# GD32A72_A74x register map
File version: 1.0
CPU: CM7 r2p1, little endian, MPU, FPU, DSP, 4 interrupt priority bits
Registers are 32-bit, read-write, reset 0x0 unless marked. A register's access mark holds for its fields unless they carry their own. Offsets are from the block's base; [hi:lo] are bit positions.

## RTC — Real-time clock
Base 0x40002800
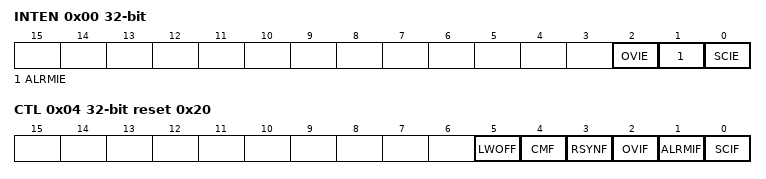
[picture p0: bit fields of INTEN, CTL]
0x00 INTEN — RTC interrupt enable register
  [2] OVIE — Overflow interrupt enable
  [1] ALRMIE — Alarm interrupt enable
  [0] SCIE — Second interrupt enable
0x04 CTL access per field reset 0x20 — RTC control register
  [5] LWOFF ro — Last write operation finished flag
  [4] CMF rw — Configuration mode flag
  [3] RSYNF rw — Registers synchronized flag
  [2] OVIF rw — Overflow interrupt flag
  [1] ALRMIF rw — Alarm interrupt flag
  [0] SCIF rw — Second interrupt flag
0x08 PSCH wo — RTC prescaler high register
  [3:0] PSC — RTC prescaler value high
0x0C PSCL wo reset 0x8000 — RTC prescaler low register
  [15:0] PSC — RTC prescaler value low
0x10 DIVH ro — RTC divider high register
  [3:0] DIV — RTC divider value high
0x14 DIVL ro reset 0x8000 — RTC divider low register
  [15:0] DIV — RTC divider value low
0x18 CNTH — RTC counter high register
  [15:0] CNT — RTC counter value high
0x1C CNTL — RTC counter low register
  [15:0] CNT — RTC counter value low
0x20 ALRMH wo reset 0xFFFF — RTC alarm high register
  [15:0] ALRM — RTC alarm value high
0x24 ALRML wo reset 0xFFFF — RTC alarm low register
  [15:0] ALRM — RTC alarm value low

## SPI0 — Serial peripheral interface
Base 0x40013000
Same registers: SPI6 0x40003800, SPI7 0x40003C00, SPI2 0x4000E400, SPI3 0x4000E800, SPI4 0x40014400, SPI5 0x40014800, SPI1 0x40017800
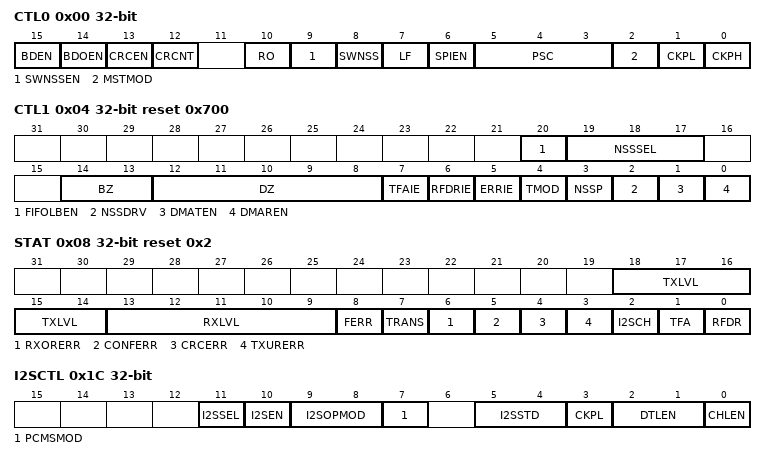
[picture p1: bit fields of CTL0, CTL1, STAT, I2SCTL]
0x00 CTL0 — Control register 0
  [15] BDEN — Bidirectional enable
  [14] BDOEN — Bidirectional transmit output enable
  [13] CRCEN — CRC calculation enable
  [12] CRCNT — CRC next transfer
  [10] RO — Receive only
  [9] SWNSSEN — NSS software mode selection
  [8] SWNSS — NSS pin selection in NSS software mode
  [7] LF — LSB first mode
  [6] SPIEN — SPI enable
  [5:3] PSC — Master clock prescaler selection
  [2] MSTMOD — Master mode enable
  [1] CKPL — Clock polarity selection
  [0] CKPH — Clock phase selection
0x04 CTL1 reset 0x700 — Control register 1
  [20] FIFOLBEN — FIFO loopback mode enable
  [19:17] NSSSEL — SPI NSS select
  [14:13] BZ — Bus access size
  [12:8] DZ — Data size
  [7] TFAIE — Transmit TXFIFO available interrupt enable
  [6] RFDRIE — Receive RXFIFO data ready interrupt enable
  [5] ERRIE — Errors interrupt enable
  [4] TMOD — SPI TI mode enable
  [3] NSSP — SPI NSS pulse mode enable
  [2] NSSDRV — Drive NSS output
  [1] DMATEN — Transmit FIFO DMA enable
  [0] DMAREN — Receive FIFO DMA enable
0x08 STAT access per field reset 0x2 — Status register
  [18:14] TXLVL ro — Transmission FIFO level
  [13:9] RXLVL ro — Receprion FIFO level
  [8] FERR rw — Format error
  [7] TRANS ro — Transmitting ongoing bit
  [6] RXORERR ro — Reception overrun error bit
  [5] CONFERR ro — SPI configuration error
  [4] CRCERR rw — SPI CRC error bit
  [3] TXURERR ro — Transmission underrun error bit
  [2] I2SCH ro — I2S channel side
  [1] TFA ro — Transmission FIFO available
  [0] RFDR ro — Reception FIFO data ready
0x0C DATA
  [31:0] DATA — Data transfer register
0x10 CRCPOLY reset 0x107 — CRC polynomial register
0x14 RCRC ro — Receive CRC register
  [31:0] RCRC — RX CRC value
0x18 TCRC ro — Transmit CRC register
  [31:0] TCRC — TX CRC value When the CRCEN bit of SPI_CTL0 is set, the hardware computes the CRC value of the transmitted bytes and saves them in TCRC register
0x1C I2SCTL — I2S control register
  [11] I2SSEL — I2S mode selection
  [10] I2SEN — I2S enable
  [9:8] I2SOPMOD — I2S operation mode
  [7] PCMSMOD — PCM frame synchronization mode
  [5:4] I2SSTD — I2S standard selection
  [3] CKPL — Idle state clock polarity
  [2:1] DTLEN — Data length
  [0] CHLEN — Channel length
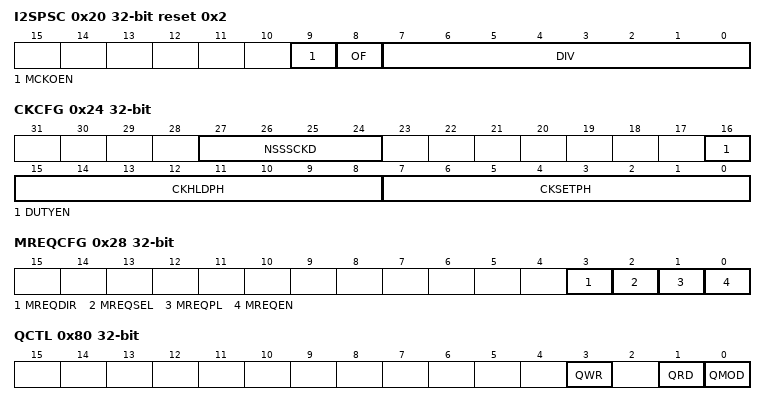
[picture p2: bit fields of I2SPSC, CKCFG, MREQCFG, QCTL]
0x20 I2SPSC reset 0x2 — I2S clock prescaler register
  [9] MCKOEN — I2S_MCK output enable
  [8] OF — Odd factor for the prescaler
  [7:0] DIV — Dividing factor for the prescaler
0x24 CKCFG — Clock configuration register
  [27:24] NSSSCKD — NSS to the first SCK edge delay
  [16] DUTYEN — SCK duty cycle enable
  [15:8] CKHLDPH — SCK hold phase
  [7:0] CKSETPH — SCK setup phase
0x28 MREQCFG — Master request configuration register
  [3] MREQDIR — MREQ pin direction
  [2] MREQSEL — Master request input source select
  [1] MREQPL — Master request polarity
  [0] MREQEN — Master request enable
0x80 QCTL — Quad-SPI mode control register
  [3] QWR — Quad-SPI mode write loopback select
  [1] QRD — Quad-SPI mode read select
  [0] QMOD — Quad-SPI mode enable
